# SAMA7D65D2GN8 register map
Vendor: Microchip Technology; Series: SAMA7D6; File version: 0
Registers are 32-bit, read-write, reset 0x0 unless marked. A register's access mark holds for its fields unless they carry their own. Offsets are from the block's base; [hi:lo] are bit positions; {n}, {i} and the like mark numbered series.

## SHDWC — Shutdown Controller
Base 0xE001D200
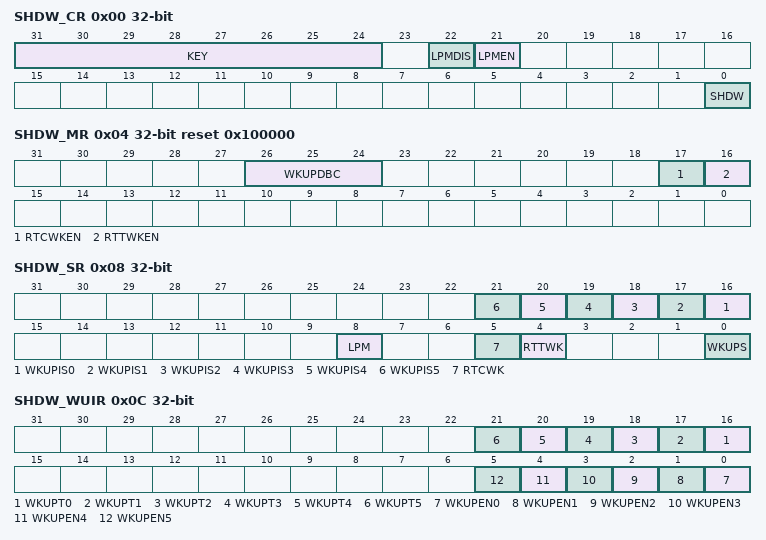
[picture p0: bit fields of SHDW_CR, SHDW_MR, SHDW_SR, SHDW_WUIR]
0x00 SHDW_CR wo — Control Register
  [31:24] KEY — Password
    165=PASSWD (Writing any other value in this field aborts the write operation.)
  [22] LPMDIS — LPM Pad Disable
    0=No effect; 1=The LPM pad is set low (external regulator is set in standard powering state)
  [21] LPMEN — LPM Pad Enable
    0=No effect; 1=The LPM pad is set high (external regulator is set in special powering state)
  [0] SHDW — Shutdown Command
    0=No effect; 1=If KEY value is correct, asserts the SHDN pin
0x04 SHDW_MR reset 0x100000 — Mode Register
  [26:24] WKUPDBC — Wake-up Inputs Debouncer Period
    0=IMMEDIATE (Immediate, no debouncing, detected active at least on one MD_SLCK edge.); 1=3_SLCK (PIOBUx shall be in its active state for at least 3 MD_SLCK periods); 2=32_SLCK (PIOBUx shall be in its active state for at least 32 MD_SLCK periods); 3=512_SLCK (PIOBUx shall be in its active state for at least 512 MD_SLCK periods); 4=4096_SLCK (PIOBUx shall be in its active state for at least 4,096 MD_SLCK periods); 5=32768_SLCK (PIOBUx shall be in its active state for at least 32,768 MD_SLCK periods)
  [17] RTCWKEN — Real-time Clock Wake-up Enable
    0=The RTC Alarm signal has no effect on the SHDWC; 1=The RTC Alarm signal forces the de-assertion of the SHDN pin
  [16] RTTWKEN — Real-time Timer Wake-up Enable
    0=The RTT Alarm signal has no effect on the SHDWC; 1=The RTT Alarm signal forces the de-assertion of the SHDN pin
0x08 SHDW_SR ro — Status Register
  [n+16] WKUPIS{n} (n=0..5) — Wake-up 0 to 5 Input Status
    0=DISABLE (The corresponding wake-up input is disabled, or was inactive at the time the debouncer triggered a wake-up event.); 1=ENABLE (The corresponding wake-up input was active at the time the debouncer triggered a wake-up event.)
  [8] LPM — Low-Power Mode Pad Status
    0=The LPM pad is currently set to 0; 1=The LPM pad is currently set to 1
  [5] RTCWK — Real-time Clock Wake-up
    0=No wake-up alarm from the RTC occurred since the last read of SHDW_SR; 1=At least one wake-up alarm from the RTC occurred since the last read of SHDW_SR
  [4] RTTWK — Real-time Timer Wake-up
    0=No wake-up alarm from the RTT occurred since the last read of SHDW_SR; 1=At least one wake-up alarm from the RTT occurred since the last read of SHDW_SR
  [0] WKUPS — Wake-up Status
    0=NO (No wake-up due to the assertion of one or more wake-up pins has occurred since the last read of SHDW_SR.); 1=PRESENT (At least one wake-up due to the assertion of one or more wake-up pins has occurred since the last read of SHDW_SR.)
0x0C SHDW_WUIR — Wake-up Inputs Register
  [n+16] WKUPT{n} (n=0..5) — Wake-up 0 to 5 Input Type
    0=LOW (A falling edge followed by a low level on the corresponding wake-up input, for a period defined by WKUPDBC, forces wake-up of the core power supply.); 1=HIGH (A rising edge followed by a high level on the corresponding wake-up input, for a period defined by WKUPDBC, forces wake-up of the core power supply.)
  [n] WKUPEN{n} (n=0..5) — Wake-up 0 to 5 Input Enable
    0=DISABLE (The corresponding wake-up input has no wake-up effect.); 1=ENABLE (The corresponding wake-up input forces wake-up of the core power supply.)
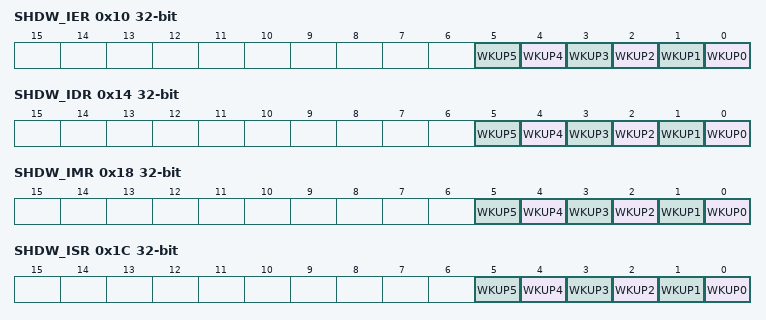
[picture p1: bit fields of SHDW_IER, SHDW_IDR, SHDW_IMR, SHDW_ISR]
0x10 SHDW_IER wo — Interrupt Enable Register
  [all] fields
    0=No effect; 1=Enables the corresponding interrupt
  [n] WKUP{n} (n=0..5) — Wake-up {n} Interrupt Enable
0x14 SHDW_IDR wo — Interrupt Disable Register
  [all] fields
    0=No effect; 1=Disables the corresponding interrupt
  [n] WKUP{n} (n=0..5) — Wake-up {n} Interrupt Disable
0x18 SHDW_IMR ro — Interrupt Mask Register
  [all] fields
    0=The corresponding interrupt is not enabled; 1=The corresponding interrupt is enabled
  [n] WKUP{n} (n=0..5) — Wake-up {n} Interrupt Mask
0x1C SHDW_ISR ro — Interrupt Status Register
  [all] fields
    0=No wake-up event has been detected on WKUPx since the last read of either SHDW_ISR or SHDW_SR; 1=At least one wake-up event has been detected on WKUPx since the last read of either SHDW_ISR or SHDW_SR
  [n] WKUP{n} (n=0..5) — Wake-up Input {n} Interrupt Status
